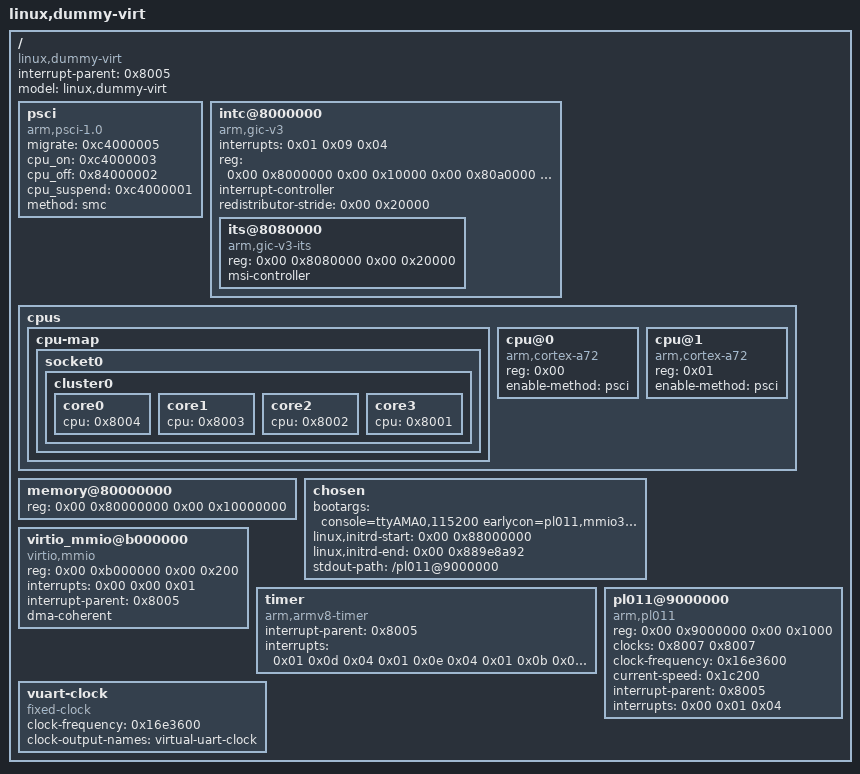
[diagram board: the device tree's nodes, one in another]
/dts-v1/;

/ {
	interrupt-parent = <0x8005>;
	model = "linux,dummy-virt";
	#size-cells = <0x02>;
	#address-cells = <0x02>;
	compatible = "linux,dummy-virt";

	psci {
		migrate = <0xc4000005>;
		cpu_on = <0xc4000003>;
		cpu_off = <0x84000002>;
		cpu_suspend = <0xc4000001>;
		method = "smc";
		compatible = "arm,psci-1.0\0arm,psci-0.2\0arm,psci";
	};

	intc@8000000 {
		phandle = <0x8005>;
		interrupts = <0x01 0x09 0x04>;
		reg = <0x00 0x8000000 0x00 0x10000 0x00 0x80a0000 0x00 0xf60000>;
		compatible = "arm,gic-v3";
		ranges;
		#size-cells = <0x02>;
		#address-cells = <0x02>;
		interrupt-controller;
		#interrupt-cells = <0x03>;
		redistributor-stride = <0x00 0x20000>;
		linux,phandle = <0x8005>;

		its@8080000 {
			phandle = <0x8006>;
			reg = <0x00 0x8080000 0x00 0x20000>;
			#msi-cells = <0x01>;
			msi-controller;
			compatible = "arm,gic-v3-its";
			linux,phandle = <0x8006>;
		};
	};

	cpus {
		#size-cells = <0x00>;
		#address-cells = <0x01>;

		cpu-map {

			socket0 {

				cluster0 {

					core0 {
						cpu = <0x8004>;
					};

					core1 {
						cpu = <0x8003>;
					};

					core2 {
						cpu = <0x8002>;
					};

					core3 {
						cpu = <0x8001>;
					};
				};
			};
		};

		cpu@0 {
			phandle = <0x8004>;
			reg = <0x00>;
			enable-method = "psci";
			compatible = "arm,cortex-a72";
			device_type = "cpu";
		};

		cpu@1 {
			phandle = <0x8003>;
			reg = <0x01>;
			enable-method = "psci";
			compatible = "arm,cortex-a72";
			device_type = "cpu";
		};
	};

	memory@80000000 {
		device_type = "memory";
		reg = <0x00 0x80000000 0x00 0x10000000>;
	};

	chosen {
		bootargs = "console=ttyAMA0,115200 earlycon=pl011,mmio32,0x9000000";
		linux,initrd-start = <0x00 0x88000000>;
		linux,initrd-end = <0x00 0x889e8a92>;
		stdout-path = "/pl011@9000000";
	};

	virtio_mmio@b000000 {
		compatible = "virtio,mmio";
		reg = <0x00 0xb000000 0x00 0x200>;
		interrupts = <0x00 0x00 0x01>;
		interrupt-parent = <0x8005>;
		dma-coherent;
	};

	timer {
		compatible = "arm,armv8-timer";
		interrupt-parent = <0x8005>;
		interrupts = <0x01 0x0d 0x04 0x01 0x0e 0x04 0x01 0x0b 0x04 0x01 0x0a 0x04>;
	};

	pl011@9000000 {
		reg = <0x00 0x9000000 0x00 0x1000>;
		compatible = "arm,pl011\0arm,primecell";
		clocks = <0x8007 0x8007>;
		clock-names = "uartclk\0apb_pclk";
		clock-frequency = <0x16e3600>;
		current-speed = <0x1c200>;
		interrupt-parent = <0x8005>;
		interrupts = <0x00 0x01 0x04>;
	};

	vuart-clock {
		compatible = "fixed-clock";
		#clock-cells = <0x00>;
		clock-frequency = <0x16e3600>;
		clock-output-names = "virtual-uart-clock";
		phandle = <0x8007>;
		linux,phandle = <0x8007>;
	};
};
